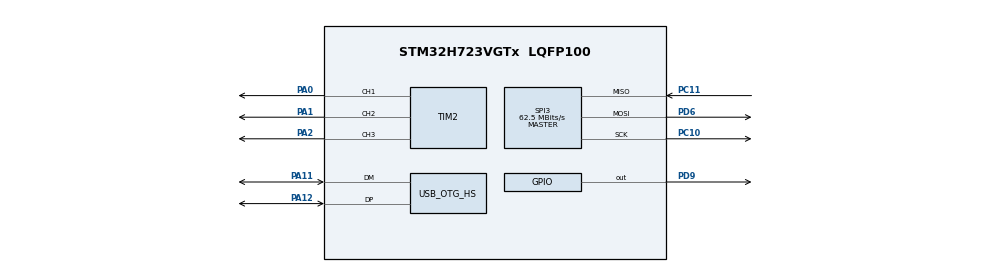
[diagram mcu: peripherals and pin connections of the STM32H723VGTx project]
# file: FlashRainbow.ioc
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CORTEX_M7.default_mode_Activation=1
Mcu.Family=STM32H7
Mcu.Name=STM32H723VGTx
Mcu.Package=LQFP100
NVIC.OTG_HS_IRQn=true\:0\:0\:false\:false\:true\:false\:true\:true
NVIC.PriorityGroup=NVIC_PRIORITYGROUP_4
PA0.Signal=S_TIM2_CH1_ETR
PA1.Signal=S_TIM2_CH2
PA11.Mode=Device_Only_FS
PA11.Signal=USB_OTG_HS_DM
PA12.Mode=Device_Only_FS
PA12.Signal=USB_OTG_HS_DP
PA13(JTMS/SWDIO).Mode=Trace_Asynchronous_SW
PA13(JTMS/SWDIO).Signal=DEBUG_JTMS-SWDIO
PA14(JTCK/SWCLK).Mode=Trace_Asynchronous_SW
PA14(JTCK/SWCLK).Signal=DEBUG_JTCK-SWCLK
PA2.Signal=S_TIM2_CH3
PB3(JTDO/TRACESWO).Mode=Trace_Asynchronous_SW
PB3(JTDO/TRACESWO).Signal=DEBUG_JTDO-SWO
PC10.Mode=Full_Duplex_Master
PC10.Signal=SPI3_SCK
PC11.Mode=Full_Duplex_Master
PC11.Signal=SPI3_MISO
PD6.Mode=Full_Duplex_Master
PD6.Signal=SPI3_MOSI
PD9.Signal=GPIO_Output
PH0-OSC_IN.Mode=HSE-External-Oscillator
PH0-OSC_IN.Signal=RCC_OSC_IN
PH1-OSC_OUT.Mode=HSE-External-Oscillator
PH1-OSC_OUT.Signal=RCC_OSC_OUT
ProjectManager.HeapSize=0x200
ProjectManager.StackSize=0x400
ProjectManager.TargetToolchain=STM32CubeIDE
RCC.ADCFreq_Value=544000000
RCC.APB1Freq_Value=125000000
RCC.APB2Freq_Value=125000000
RCC.APB3Freq_Value=125000000
RCC.APB4Freq_Value=125000000
RCC.CortexFreq_Value=250000000
RCC.D1PPRE=RCC_APB3_DIV2
RCC.D2PPRE1=RCC_APB1_DIV2
RCC.D2PPRE2=RCC_APB2_DIV2
RCC.D3PPRE=RCC_APB4_DIV2
RCC.DIVM1=1
RCC.DIVM2=2
RCC.DIVM3=2
RCC.DIVN1=15
RCC.DIVN2=68
RCC.DIVN3=68
RCC.DIVP1=1
RCC.DIVP2=1
RCC.DIVP3=1
RCC.DIVR1=1
RCC.HCLKFreq_Value=250000000
RCC.HSE_VALUE=16000000
RCC.PLLFRACN=5120
RCC.PLLSourceVirtual=RCC_PLLSOURCE_HSE
RCC.SYSCLKFreq_VALUE=250000000
RCC.SYSCLKSource=RCC_SYSCLKSOURCE_PLLCLK
RCC.USBFreq_Value=125000000
SH.S_TIM2_CH1_ETR.0=TIM2_CH1,PWM Generation1 CH1
SH.S_TIM2_CH2.0=TIM2_CH2,PWM Generation2 CH2
SH.S_TIM2_CH3.0=TIM2_CH3,PWM Generation3 CH3
SPI3.BaudRatePrescaler=SPI_BAUDRATEPRESCALER_2
SPI3.CLKPhase=SPI_PHASE_2EDGE
SPI3.CLKPolarity=SPI_POLARITY_HIGH
SPI3.CalculateBaudRate=62.5 MBits/s
SPI3.DataSize=SPI_DATASIZE_8BIT
SPI3.Direction=SPI_DIRECTION_2LINES
SPI3.Mode=SPI_MODE_MASTER
SPI3.VirtualType=VM_MASTER
TIM2.Channel-PWM\ Generation1\ CH1=TIM_CHANNEL_1
TIM2.Channel-PWM\ Generation2\ CH2=TIM_CHANNEL_2
TIM2.Channel-PWM\ Generation3\ CH3=TIM_CHANNEL_3
TIM2.OCFastMode_PWM-PWM\ Generation1\ CH1=TIM_OCFAST_ENABLE
TIM2.OCFastMode_PWM-PWM\ Generation2\ CH2=TIM_OCFAST_ENABLE
TIM2.OCFastMode_PWM-PWM\ Generation3\ CH3=TIM_OCFAST_ENABLE
TIM2.OCPolarity_1=TIM_OCPOLARITY_LOW
TIM2.OCPolarity_2=TIM_OCPOLARITY_LOW
TIM2.OCPolarity_3=TIM_OCPOLARITY_LOW
USB_DEVICE.CLASS_NAME_HS=CDC
USB_DEVICE.MANUFACTURER_STRING=Longhorn Racing Electric
USB_DEVICE.PRODUCT_STRING_CDC_HS=LHRe HVC
USB_DEVICE.VirtualMode=Cdc
USB_DEVICE.VirtualModeHS=Cdc_HS
USB_OTG_HS.VirtualMode-Device_Only_FS=Device_Only_FS
VP_MEMORYMAP_VS_MEMORYMAP.Mode=CurAppReg
VP_USB_DEVICE_VS_USB_DEVICE_CDC_HS.Mode=CDC_HS
board=custom

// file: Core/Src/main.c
/* USER CODE BEGIN Header */
/**
  ******************************************************************************
  * @file           : main.c
  * @brief          : Main program body
  ******************************************************************************
  * @attention
  *
  * Copyright (c) 2025 STMicroelectronics.
  * All rights reserved.
  *
  * This software is licensed under terms that can be found in the LICENSE file
  * in the root directory of this software component.
  * If no LICENSE file comes with this software, it is provided AS-IS.
  *
  ******************************************************************************
  */
/* USER CODE END Header */
#include "main.h"
#include "memorymap.h"
#include "spi.h"
#include "tim.h"
#include "usb_device.h"
#include "gpio.h"

/* USER CODE BEGIN Includes */
#include "usb_vcp.h"
#include "dfu.h"
#include "led.h"
#include "timer.h"

/* USER CODE END Includes */

void SystemClock_Config(void);
static void MPU_Config(void);

int main(void)
{

  /* MPU Configuration--------------------------------------------------------*/
  MPU_Config();

  /* MCU Configuration--------------------------------------------------------*/

  /* Reset of all peripherals, Initializes the Flash interface and the Systick. */
  HAL_Init();

  /* USER CODE BEGIN Init */

  // TEST 2: VERIFIED CS TOGGLING
  // GPIO_InitTypeDef GPIO_InitStruct = {0};
  // GPIO_InitStruct.Pin = GPIO_PIN_9;
  // GPIO_InitStruct.Mode = GPIO_MODE_OUTPUT_PP;
  // GPIO_InitStruct.Pull = GPIO_NOPULL;
  // GPIO_InitStruct.Speed = GPIO_SPEED_FREQ_LOW;
  // HAL_GPIO_Init(GPIOD, &GPIO_InitStruct);

  // FINAL TEST: COME BACK HERE TO FIX CALL
  //
  // // Initialize SPI3 - VERY IMPORTANT - Use the function generated by STM32CubeIDE
  //
  // // Read STATUSA
  // uint32_t status = adbms_read_statusa();
  //
  // if (status == 0xFFFFFFFF) {
  //   printf("PEC Error reading STATUSA!\n");
  // } else {
  //   printf("STATUSA: 0x%08X\n", (unsigned int)status);
  // }

  /* USER CODE END Init */

  /* Configure the system clock */
  SystemClock_Config();

  /* USER CODE BEGIN SysInit */
  dfu_init(GPIOA, GPIO_PIN_15); // replace GPIOA and PIN_15 with the correct GPIOX/pin for BOOT0trig
  /* USER CODE END SysInit */

  /* Initialize all configured peripherals */
  MX_GPIO_Init();
  MX_SPI3_Init();
  MX_USB_DEVICE_Init();
  MX_TIM2_Init();
  /* USER CODE BEGIN 2 */
  usb_printf("String %d", 15/*value*/); // works just like printf, use like printf, vcp code
  /* USER CODE END 2 */

  /* Infinite loop */
  /* USER CODE BEGIN WHILE */

  // TEST 3: TESTING SIMPLE SPI MESSAGE

  // Variables for testing
  //uint8_t tx_data[4] = {CMD_READ_REG, 0x00, 0x00, 0x41}; // Example command + PEC
  uint8_t rx_data[6] = {0}; // Buffer for received data

  while (1)
  {
    /* USER CODE END WHILE */

    /* USER CODE BEGIN 3 */
    receive_periodic(); //dfu code
    // DEFAULT: Toggle LED rainbow
    HAL_GPIO_TogglePin(GPIOA, GPIO_PIN_0);
    HAL_Delay(100); // 1 second delay

    HAL_GPIO_TogglePin(GPIOA, GPIO_PIN_1);
    HAL_Delay(100);

    HAL_GPIO_TogglePin(GPIOA, GPIO_PIN_2);
    HAL_Delay(100);

// TEST 3: TESTING ISOSPI

      // Pull CS Low
      // HAL_GPIO_WritePin(CS_GPIO_Port, CS_Pin, GPIO_PIN_RESET);
      //
      // // Send Command
      // HAL_SPI_Transmit(&hspi3, tx_data, sizeof(tx_data), HAL_MAX_DELAY);
      //
      // // Receive Response
      // HAL_SPI_Receive(&hspi3, rx_data, sizeof(rx_data), HAL_MAX_DELAY);
      //
      // // Pull CS High
      // HAL_GPIO_WritePin(CS_GPIO_Port, CS_Pin, GPIO_PIN_SET);
      //
      // HAL_Delay(1000); // Delay for visibility

    // TEST 2: CS SIGNAL SUCCESSFUL
  // HAL_GPIO_WritePin(CS_GPIO_Port, CS_Pin, GPIO_PIN_SET);  // Set PD9 high
  // HAL_Delay(100); // Wait 500ms
  // HAL_GPIO_WritePin(CS_GPIO_Port, CS_Pin, GPIO_PIN_RESET); // Set PD9 low
  // HAL_Delay(100); // Wait 500ms
  }
  /* USER CODE END 3 */
}

void SystemClock_Config(void)
{
  RCC_OscInitTypeDef RCC_OscInitStruct = {0};
  RCC_ClkInitTypeDef RCC_ClkInitStruct = {0};

  /** Supply configuration update enable
  */
  HAL_PWREx_ConfigSupply(PWR_LDO_SUPPLY);

  /** Configure the main internal regulator output voltage
  */
  __HAL_PWR_VOLTAGESCALING_CONFIG(PWR_REGULATOR_VOLTAGE_SCALE0);

  while(!__HAL_PWR_GET_FLAG(PWR_FLAG_VOSRDY)) {}

  /** Initializes the RCC Oscillators according to the specified parameters
  * in the RCC_OscInitTypeDef structure.
  */
  RCC_OscInitStruct.OscillatorType = RCC_OSCILLATORTYPE_HSE;
  RCC_OscInitStruct.HSEState = RCC_HSE_ON;
  RCC_OscInitStruct.PLL.PLLState = RCC_PLL_ON;
  RCC_OscInitStruct.PLL.PLLSource = RCC_PLLSOURCE_HSE;
  RCC_OscInitStruct.PLL.PLLM = 1;
  RCC_OscInitStruct.PLL.PLLN = 15;
  RCC_OscInitStruct.PLL.PLLP = 1;
  RCC_OscInitStruct.PLL.PLLQ = 2;
  RCC_OscInitStruct.PLL.PLLR = 1;
  RCC_OscInitStruct.PLL.PLLRGE = RCC_PLL1VCIRANGE_3;
  RCC_OscInitStruct.PLL.PLLVCOSEL = RCC_PLL1VCOWIDE;
  RCC_OscInitStruct.PLL.PLLFRACN = 5120;
  if (HAL_RCC_OscConfig(&RCC_OscInitStruct) != HAL_OK)
  {
    Error_Handler();
  }

  /** Initializes the CPU, AHB and APB buses clocks
  */
  RCC_ClkInitStruct.ClockType = RCC_CLOCKTYPE_HCLK|RCC_CLOCKTYPE_SYSCLK
                              |RCC_CLOCKTYPE_PCLK1|RCC_CLOCKTYPE_PCLK2
                              |RCC_CLOCKTYPE_D3PCLK1|RCC_CLOCKTYPE_D1PCLK1;
  RCC_ClkInitStruct.SYSCLKSource = RCC_SYSCLKSOURCE_PLLCLK;
  RCC_ClkInitStruct.SYSCLKDivider = RCC_SYSCLK_DIV1;
  RCC_ClkInitStruct.AHBCLKDivider = RCC_HCLK_DIV1;
  RCC_ClkInitStruct.APB3CLKDivider = RCC_APB3_DIV2;
  RCC_ClkInitStruct.APB1CLKDivider = RCC_APB1_DIV2;
  RCC_ClkInitStruct.APB2CLKDivider = RCC_APB2_DIV2;
  RCC_ClkInitStruct.APB4CLKDivider = RCC_APB4_DIV2;

  if (HAL_RCC_ClockConfig(&RCC_ClkInitStruct, FLASH_LATENCY_3) != HAL_OK)
  {
    Error_Handler();
  }
}

 /* MPU Configuration */

void MPU_Config(void)
{
  MPU_Region_InitTypeDef MPU_InitStruct = {0};

  /* Disables the MPU */
  HAL_MPU_Disable();

  /** Initializes and configures the Region and the memory to be protected
  */
  MPU_InitStruct.Enable = MPU_REGION_ENABLE;
  MPU_InitStruct.Number = MPU_REGION_NUMBER0;
  MPU_InitStruct.BaseAddress = 0x0;
  MPU_InitStruct.Size = MPU_REGION_SIZE_4GB;
  MPU_InitStruct.SubRegionDisable = 0x87;
  MPU_InitStruct.TypeExtField = MPU_TEX_LEVEL0;
  MPU_InitStruct.AccessPermission = MPU_REGION_NO_ACCESS;
  MPU_InitStruct.DisableExec = MPU_INSTRUCTION_ACCESS_DISABLE;
  MPU_InitStruct.IsShareable = MPU_ACCESS_SHAREABLE;
  MPU_InitStruct.IsCacheable = MPU_ACCESS_NOT_CACHEABLE;
  MPU_InitStruct.IsBufferable = MPU_ACCESS_NOT_BUFFERABLE;

  HAL_MPU_ConfigRegion(&MPU_InitStruct);
  /* Enables the MPU */
  HAL_MPU_Enable(MPU_PRIVILEGED_DEFAULT);

}

void Error_Handler(void)
{
  __disable_irq();
  while (1)
  {
  }
}
